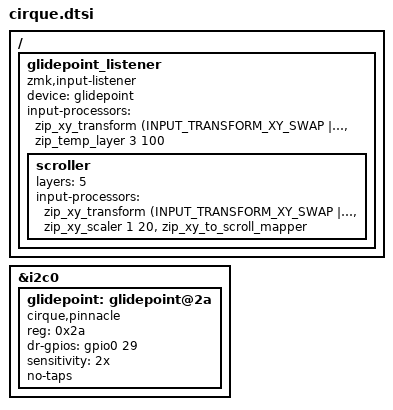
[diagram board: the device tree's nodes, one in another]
#include <input/processors.dtsi>
#include <dt-bindings/zmk/input_transform.h>

&i2c0 {
    status = "okay";

    glidepoint: glidepoint@2a {
        compatible = "cirque,pinnacle";
        reg = <0x2a>;
        status = "okay";
        dr-gpios = <&gpio0 29 (GPIO_ACTIVE_HIGH)>;

        sensitivity = "2x";
        // sleep;
        no-taps;
    };
};


/ {
    glidepoint_listener: glidepoint_listener {
        compatible = "zmk,input-listener";
        status = "okay";
        device = <&glidepoint>;
        input-processors = <
            &zip_xy_transform (INPUT_TRANSFORM_XY_SWAP | INPUT_TRANSFORM_Y_INVERT)
            &zip_temp_layer 3 100
        >;
        scroller {
            layers = <5>;
            input-processors = <
                &zip_xy_transform (INPUT_TRANSFORM_XY_SWAP | INPUT_TRANSFORM_X_INVERT)
                &zip_xy_scaler 1 20
                &zip_xy_to_scroll_mapper
            >;
        };
    };
};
